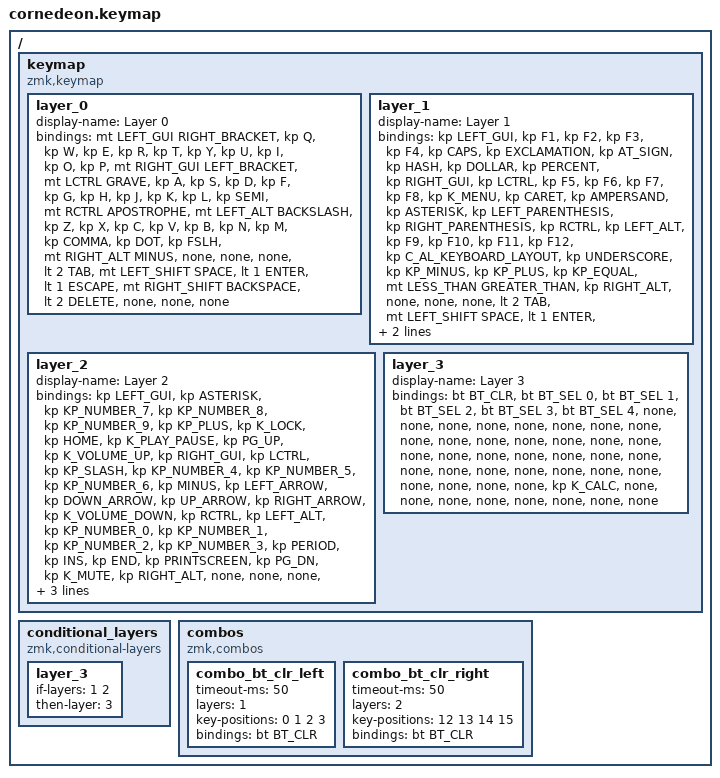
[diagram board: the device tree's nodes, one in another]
/*
 * Copyright (c) 2020 The ZMK Contributors
 *
 * SPDX-License-Identifier: MIT
 */

#include <dt-bindings/zmk/matrix_transform.h>
#include <behaviors.dtsi>
#include <dt-bindings/zmk/bt.h>
#include <dt-bindings/zmk/keys.h>

/ {
    keymap {
        compatible = "zmk,keymap";

        layer_0 {
            display-name = "Layer 0";

            // ----------------------------------------------------------------------------------------
            // |  ESC  |  Q   |  W  |   E  |   R   |  T  |   |  Y  |   U   |  I  |  O  |  P   | BSPC  |
            // |  TAB  |  A   |  S  |   D  |   F   |  G  |   |  H  |   J   |  K  |  L  |  ;   |   '   |
            // | SHIFT |  Z   |  X  |   C  |   V   |  B  |   |  N  |   M   |  ,  |  .  |  /   | SHIFT |
            // | CTRL  | LEFT |RIGHT| LALT | MO(1) | SPC |   | SPC | MO(2) | GUI | UP  | DOWN | CTRL  |

            bindings = <
&mt LEFT_GUI RIGHT_BRACKET  &kp Q  &kp W  &kp E  &kp R  &kp T  &kp Y  &kp U  &kp I  &kp O  &kp P  &mt RIGHT_GUI LEFT_BRACKET  &mt LCTRL GRAVE  &kp A  &kp S  &kp D  &kp F  &kp G  &kp H  &kp J  &kp K  &kp L  &kp SEMI  &mt RCTRL APOSTROPHE  &mt LEFT_ALT BACKSLASH  &kp Z  &kp X  &kp C  &kp V  &kp B  &kp N  &kp M  &kp COMMA  &kp DOT  &kp FSLH  &mt RIGHT_ALT MINUS  &none  &none  &none  &lt 2 TAB  &mt LEFT_SHIFT SPACE  &lt 1 ENTER  &lt 1 ESCAPE  &mt RIGHT_SHIFT BACKSPACE  &lt 2 DELETE  &none  &none  &none
            >;
        };

        layer_1 {
            display-name = "Layer 1";

            // -------------------------------------------------------------------------------------
            // |  ESC  |  ~   |  (  |  )  |  *  |  /  |      |  7  |  8  |  9  |  0  | INS |  DEL  |
            // |  TAB  |      |  [  |  ]  |  +  |  -  |      |  4  |  5  |  6  |  .  |  /  |   \   |
            // | SHIFT |      |  {  |  }  |  <  |  >  |      |  1  |  2  |  3  |  =  |  _  | SHIFT |
            // | CTRL  | HOME | END | ALT |     | RET |      | RET |     | GUI | PUP | PDN | CTRL  |

            bindings = <
&kp LEFT_GUI  &kp F1  &kp F2  &kp F3  &kp F4  &kp CAPS  &kp EXCLAMATION  &kp AT_SIGN  &kp HASH  &kp DOLLAR  &kp PERCENT  &kp RIGHT_GUI  &kp LCTRL  &kp F5  &kp F6  &kp F7  &kp F8  &kp K_MENU  &kp CARET  &kp AMPERSAND  &kp ASTERISK  &kp LEFT_PARENTHESIS  &kp RIGHT_PARENTHESIS  &kp RCTRL  &kp LEFT_ALT  &kp F9  &kp F10  &kp F11  &kp F12  &kp C_AL_KEYBOARD_LAYOUT  &kp UNDERSCORE  &kp KP_MINUS  &kp KP_PLUS  &kp KP_EQUAL  &mt LESS_THAN GREATER_THAN  &kp RIGHT_ALT  &none  &none  &none  &lt 2 TAB  &mt LEFT_SHIFT SPACE  &lt 1 ENTER  &lt 1 ESCAPE  &mt RIGHT_SHIFT BACKSPACE  &lt 2 DELETE  &none  &none  &none
            >;
        };

        layer_2 {
            display-name = "Layer 2";

            // ------------------------------------------------------------------------------------------
            // |   *   |  /   |  0  |  7  |  8  |  9  |      |  F7 |  F8  |  F9 |  F10 |  PSCRN | PAUSE |
            // |   +   |  -   |  .  |  4  |  5  |  6  |      |  F4 |  F5  |  F6 |  F11 |  NUMLK | SCRLK |
            // | SHIFT |      |  =  |  1  |  2  |  3  |      |  F1 |  F2  |  F3 |  F12 |   MENU | SHIFT |
            // | CTRL  | HOME | END | ALT |     | RET |      | RET |      | CAPS|  PUP |   PDN  |  CTRL |

            bindings = <
&kp LEFT_GUI  &kp ASTERISK  &kp KP_NUMBER_7  &kp KP_NUMBER_8  &kp KP_NUMBER_9  &kp KP_PLUS  &kp K_LOCK  &kp HOME  &kp K_PLAY_PAUSE  &kp PG_UP  &kp K_VOLUME_UP  &kp RIGHT_GUI  &kp LCTRL  &kp KP_SLASH  &kp KP_NUMBER_4  &kp KP_NUMBER_5  &kp KP_NUMBER_6  &kp MINUS  &kp LEFT_ARROW  &kp DOWN_ARROW  &kp UP_ARROW  &kp RIGHT_ARROW  &kp K_VOLUME_DOWN  &kp RCTRL  &kp LEFT_ALT  &kp KP_NUMBER_0  &kp KP_NUMBER_1  &kp KP_NUMBER_2  &kp KP_NUMBER_3  &kp PERIOD  &kp INS  &kp END  &kp PRINTSCREEN  &kp PG_DN  &kp K_MUTE  &kp RIGHT_ALT  &none  &none  &none  &lt 2 TAB  &mt LEFT_SHIFT SPACE  &lt 1 ENTER  &lt 1 ESCAPE  &mt RIGHT_SHIFT BACKSPACE  &lt 2 DELETE  &none  &none  &none
            >;
        };

        layer_3 {
            display-name = "Layer 3";

            // -----------------------------------------------------------------------------------
            // | BTCLR | BT0 | BT1 | BT2  | BT3 | BT4 |      |     |     |     |     |     |     |
            // |       |     |     |      |     |     |      |     |     |     |     |     |     |
            // |       |     |     |      |     |     |      |     |     |     |     |     |     |
            // |       |     |     | CALC |     |     |      |     |     |     |     |     |     |

            bindings = <
&bt BT_CLR  &bt BT_SEL 0  &bt BT_SEL 1  &bt BT_SEL 2  &bt BT_SEL 3  &bt BT_SEL 4  &none  &none  &none  &none  &none  &none  &none  &none  &none  &none  &none  &none  &none  &none  &none  &none  &none  &none  &none  &none  &none  &none  &none  &none  &none  &none  &none  &none  &none  &none  &none  &none  &none  &kp K_CALC  &none  &none  &none  &none  &none  &none  &none  &none
            >;
        };
    };

    conditional_layers {
        compatible = "zmk,conditional-layers";

        layer_3 {
            if-layers = <1 2>;
            then-layer = <3>;
        };
    };

    combos {
        compatible = "zmk,combos";

        combo_bt_clr_left {
            timeout-ms = <50>;
            layers = <1>;
            key-positions = <0 1 2 3>;
            bindings = <&bt BT_CLR>;
        };

        combo_bt_clr_right {
            timeout-ms = <50>;
            layers = <2>;
            key-positions = <12 13 14 15>;
            bindings = <&bt BT_CLR>;
        };
    };
};
